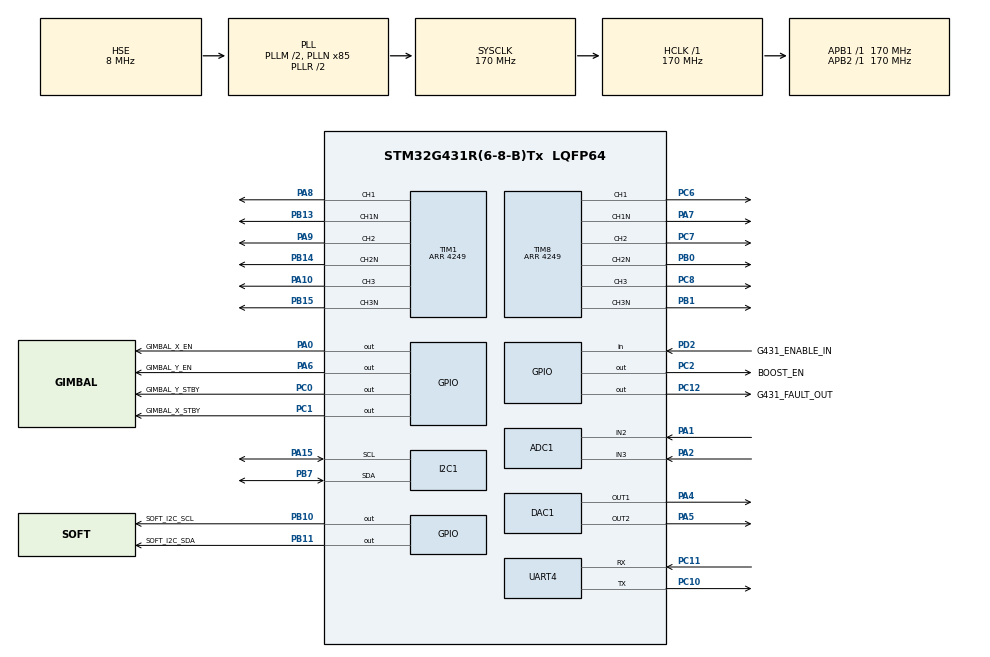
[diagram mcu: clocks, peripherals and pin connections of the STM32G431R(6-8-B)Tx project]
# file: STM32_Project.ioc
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ADC1.Channel-0\#ChannelRegularConversion=ADC_CHANNEL_2
ADC1.Channel-1\#ChannelRegularConversion=ADC_CHANNEL_3
ADC1.NbrOfConversion=2
ADC1.NbrOfConversionFlag=1
ADC1.OffsetNumber-0\#ChannelRegularConversion=ADC_OFFSET_NONE
ADC1.OffsetNumber-1\#ChannelRegularConversion=ADC_OFFSET_NONE
ADC1.Rank-0\#ChannelRegularConversion=1
ADC1.Rank-1\#ChannelRegularConversion=2
ADC1.SamplingTime-0\#ChannelRegularConversion=ADC_SAMPLETIME_92CYCLES_5
ADC1.SamplingTime-1\#ChannelRegularConversion=ADC_SAMPLETIME_92CYCLES_5
ADC1.master=1
DAC1.DAC_Channel-DAC_OUT2=DAC_CHANNEL_2
I2C1.Timing=0x40B285C2
Mcu.Family=STM32G4
Mcu.Name=STM32G431R(6-8-B)Tx
Mcu.Package=LQFP64
NVIC.PriorityGroup=NVIC_PRIORITYGROUP_4
PA0.GPIO_Label=GIMBAL_X_EN
PA0.GPIO_ModeDefaultOutputPP=GPIO_MODE_OUTPUT_OD
PA0.Signal=GPIO_Output
PA1.Mode=IN2-Single-Ended
PA1.Signal=ADC1_IN2
PA10.Signal=S_TIM1_CH3
PA13.Mode=Serial_Wire
PA13.Signal=SYS_JTMS-SWDIO
PA14.Mode=Serial_Wire
PA14.Signal=SYS_JTCK-SWCLK
PA15.Mode=I2C
PA15.Signal=I2C1_SCL
PA2.Mode=IN3-Single-Ended
PA2.Signal=ADC1_IN3
PA4.Signal=COMP_DAC11_group
PA5.Signal=COMP_DAC12_group
PA6.GPIO_Label=GIMBAL_Y_EN
PA6.GPIO_ModeDefaultOutputPP=GPIO_MODE_OUTPUT_OD
PA6.Signal=GPIO_Output
PA7.Mode=PWM Generation1 CH1 CH1N
PA7.Signal=TIM8_CH1N
PA8.Signal=S_TIM1_CH1
PA9.Signal=S_TIM1_CH2
PB0.Mode=PWM Generation2 CH2 CH2N
PB0.Signal=TIM8_CH2N
PB1.Mode=PWM Generation3 CH3 CH3N
PB1.Signal=TIM8_CH3N
PB10.GPIO_Label=SOFT_I2C_SCL
PB10.GPIO_ModeDefaultOutputPP=GPIO_MODE_OUTPUT_OD
PB10.GPIO_PuPd=GPIO_NOPULL
PB10.PinState=GPIO_PIN_SET
PB10.Signal=GPIO_Output
PB11.GPIO_Label=SOFT_I2C_SDA
PB11.GPIO_ModeDefaultOutputPP=GPIO_MODE_OUTPUT_OD
PB11.GPIO_PuPd=GPIO_NOPULL
PB11.PinState=GPIO_PIN_SET
PB11.Signal=GPIO_Output
PB13.Mode=PWM Generation1 CH1 CH1N
PB13.Signal=TIM1_CH1N
PB14.Mode=PWM Generation2 CH2 CH2N
PB14.Signal=TIM1_CH2N
PB15.Mode=PWM Generation3 CH3 CH3N
PB15.Signal=TIM1_CH3N
PB7.Mode=I2C
PB7.Signal=I2C1_SDA
PC0.GPIO_Label=GIMBAL_Y_STBY
PC0.Signal=GPIO_Output
PC1.GPIO_Label=GIMBAL_X_STBY
PC1.Signal=GPIO_Output
PC10.Mode=Asynchronous
PC10.Signal=UART4_TX
PC11.Mode=Asynchronous
PC11.Signal=UART4_RX
PC12.GPIO_Label=G431_FAULT_OUT
PC12.Signal=GPIO_Output
PC2.GPIO_Label=BOOST_EN
PC2.Signal=GPIO_Output
PC6.Signal=S_TIM8_CH1
PC7.Signal=S_TIM8_CH2
PC8.Signal=S_TIM8_CH3
PD2.GPIO_Label=G431_ENABLE_IN
PD2.Signal=GPIO_Input
PF0-OSC_IN.Mode=HSE-External-Oscillator
PF0-OSC_IN.Signal=RCC_OSC_IN
PF1-OSC_OUT.Mode=HSE-External-Oscillator
PF1-OSC_OUT.Signal=RCC_OSC_OUT
ProjectManager.HeapSize=0x200
ProjectManager.StackSize=0x400
ProjectManager.TargetToolchain=CMake
RCC.ADC12Freq_Value=170000000
RCC.AHBFreq_Value=170000000
RCC.APB1Freq_Value=170000000
RCC.APB1TimFreq_Value=170000000
RCC.APB2Freq_Value=170000000
RCC.APB2TimFreq_Value=170000000
RCC.CortexFreq_Value=170000000
RCC.EXTERNAL_CLOCK_VALUE=12288000
RCC.HCLKFreq_Value=170000000
RCC.HSE_VALUE=8000000
RCC.HSI48_VALUE=48000000
RCC.HSI_VALUE=16000000
RCC.LSE_VALUE=32768
RCC.PLLM=RCC_PLLM_DIV2
RCC.PLLN=85
RCC.PLLSourceVirtual=RCC_PLLSOURCE_HSE
RCC.SYSCLKFreq_VALUE=170000000
RCC.SYSCLKSource=RCC_SYSCLKSOURCE_PLLCLK
RCC.USBFreq_Value=170000000
RCC.VCOOutputFreq_Value=340000000
SH.COMP_DAC11_group.0=DAC1_OUT1,DAC_OUT1
SH.COMP_DAC12_group.0=DAC1_OUT2,DAC_OUT2
SH.S_TIM1_CH1.0=TIM1_CH1,PWM Generation1 CH1 CH1N
SH.S_TIM1_CH2.0=TIM1_CH2,PWM Generation2 CH2 CH2N
SH.S_TIM1_CH3.0=TIM1_CH3,PWM Generation3 CH3 CH3N
SH.S_TIM8_CH1.0=TIM8_CH1,PWM Generation1 CH1 CH1N
SH.S_TIM8_CH2.0=TIM8_CH2,PWM Generation2 CH2 CH2N
SH.S_TIM8_CH3.0=TIM8_CH3,PWM Generation3 CH3 CH3N
TIM1.AutoReloadPreload=TIM_AUTORELOAD_PRELOAD_ENABLE
TIM1.Channel-PWM\ Generation1\ CH1\ CH1N=TIM_CHANNEL_1
TIM1.Channel-PWM\ Generation2\ CH2\ CH2N=TIM_CHANNEL_2
TIM1.Channel-PWM\ Generation3\ CH3\ CH3N=TIM_CHANNEL_3
TIM1.CounterMode=TIM_COUNTERMODE_CENTERALIGNED1
TIM1.DeadTime=85
TIM1.PeriodNoDither=4249
TIM8.AutoReloadPreload=TIM_AUTORELOAD_PRELOAD_ENABLE
TIM8.Channel-PWM\ Generation1\ CH1\ CH1N=TIM_CHANNEL_1
TIM8.Channel-PWM\ Generation2\ CH2\ CH2N=TIM_CHANNEL_2
TIM8.Channel-PWM\ Generation3\ CH3\ CH3N=TIM_CHANNEL_3
TIM8.CounterMode=TIM_COUNTERMODE_CENTERALIGNED1
TIM8.DeadTime=85
TIM8.PeriodNoDither=4249
TIM8.PulseNoDither_1=0
TIM8.PulseNoDither_2=0
VP_SYS_VS_DBSignals.Mode=DisableDeadBatterySignals
VP_TIM1_VS_ClockSourceINT.Mode=Internal
VP_TIM8_VS_ClockSourceINT.Mode=Internal
board=custom

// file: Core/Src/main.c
/* USER CODE BEGIN Header */
/**
  ******************************************************************************
  * @file           : main.c
  * @brief          : Main program body
  ******************************************************************************
  * @attention
  *
  * Copyright (c) 2026 STMicroelectronics.
  * All rights reserved.
  *
  * This software is licensed under terms that can be found in the LICENSE file
  * in the root directory of this software component.
  * If no LICENSE file comes with this software, it is provided AS-IS.
  *
  ******************************************************************************
  */
/* USER CODE END Header */
#include "main.h"
#include "adc.h"
#include "dac.h"
#include "i2c.h"
#include "tim.h"
#include "usart.h"
#include "gpio.h"

/* USER CODE BEGIN Includes */
#include "app_gimbal.h"

/* USER CODE END Includes */

void SystemClock_Config(void);

int main(void)
{

  /* MCU Configuration--------------------------------------------------------*/

  /* Reset of all peripherals, Initializes the Flash interface and the Systick. */
  HAL_Init();

  /* Configure the system clock */
  SystemClock_Config();

  /* Initialize all configured peripherals */
  MX_GPIO_Init();
  MX_ADC1_Init();
  MX_DAC1_Init();
  MX_I2C1_Init();
  MX_TIM1_Init();
  MX_TIM8_Init();
  MX_UART4_Init();
  /* USER CODE BEGIN 2 */
  app_gimbal_init();
  /* USER CODE END 2 */

  /* Infinite loop */
  while (1)
  {

    /* USER CODE BEGIN 3 */
    app_gimbal_process();
  }
  /* USER CODE END 3 */
}

void SystemClock_Config(void)
{
  RCC_OscInitTypeDef RCC_OscInitStruct = {0};
  RCC_ClkInitTypeDef RCC_ClkInitStruct = {0};

  /** Configure the main internal regulator output voltage
  */
  HAL_PWREx_ControlVoltageScaling(PWR_REGULATOR_VOLTAGE_SCALE1_BOOST);

  /** Initializes the RCC Oscillators according to the specified parameters
  * in the RCC_OscInitTypeDef structure.
  */
  RCC_OscInitStruct.OscillatorType = RCC_OSCILLATORTYPE_HSE;
  RCC_OscInitStruct.HSEState = RCC_HSE_ON;
  RCC_OscInitStruct.PLL.PLLState = RCC_PLL_ON;
  RCC_OscInitStruct.PLL.PLLSource = RCC_PLLSOURCE_HSE;
  RCC_OscInitStruct.PLL.PLLM = RCC_PLLM_DIV2;
  RCC_OscInitStruct.PLL.PLLN = 85;
  RCC_OscInitStruct.PLL.PLLP = RCC_PLLP_DIV2;
  RCC_OscInitStruct.PLL.PLLQ = RCC_PLLQ_DIV2;
  RCC_OscInitStruct.PLL.PLLR = RCC_PLLR_DIV2;
  if (HAL_RCC_OscConfig(&RCC_OscInitStruct) != HAL_OK)
  {
    Error_Handler();
  }

  /** Initializes the CPU, AHB and APB buses clocks
  */
  RCC_ClkInitStruct.ClockType = RCC_CLOCKTYPE_HCLK|RCC_CLOCKTYPE_SYSCLK
                              |RCC_CLOCKTYPE_PCLK1|RCC_CLOCKTYPE_PCLK2;
  RCC_ClkInitStruct.SYSCLKSource = RCC_SYSCLKSOURCE_PLLCLK;
  RCC_ClkInitStruct.AHBCLKDivider = RCC_SYSCLK_DIV1;
  RCC_ClkInitStruct.APB1CLKDivider = RCC_HCLK_DIV1;
  RCC_ClkInitStruct.APB2CLKDivider = RCC_HCLK_DIV1;

  if (HAL_RCC_ClockConfig(&RCC_ClkInitStruct, FLASH_LATENCY_4) != HAL_OK)
  {
    Error_Handler();
  }
}

void Error_Handler(void)
{
  __disable_irq();
  while (1)
  {
  }
}
